# M36B register map
File version: 0.1
CPU: 
Registers are 32-bit, read-write, reset 0x0 unless marked. A register's access mark holds for its fields unless they carry their own. Offsets are from the block's base; [hi:lo] are bit positions; {n}, {i} and the like mark numbered series.

## PI — General Purpose Input_Output Port (PI)
Base 0x400C0800
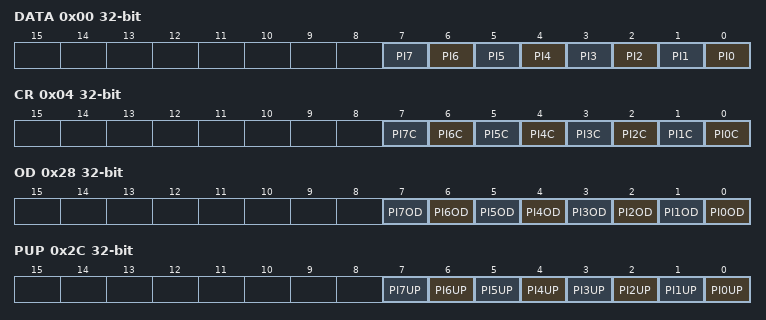
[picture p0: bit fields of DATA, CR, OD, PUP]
0x00 DATA — PI Data Register
  [n] PI{n} (n=0..7)
0x04 CR — PI Control Register
  [n] PI{n}C (n=0..7)
0x28 OD — PI Open Drain Control Register
  [n] PI{n}OD (n=0..7)
0x2C PUP — PI Pull-Up Control Register
  [n] PI{n}UP (n=0..7)
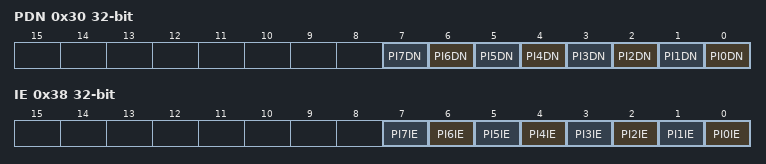
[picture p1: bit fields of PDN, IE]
0x30 PDN — PI Pull-Down Control Register
  [n] PI{n}DN (n=0..7)
0x38 IE — PI Input Enable Control Register
  [n] PI{n}IE (n=0..7)

## PJ — General Purpose Input_Output Port (PJ)
Base 0x400C0900
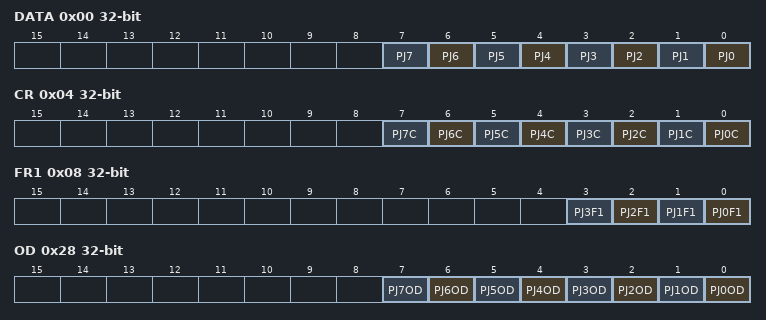
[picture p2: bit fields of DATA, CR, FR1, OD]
0x00 DATA — PJ Data Register
  [n] PJ{n} (n=0..7)
0x04 CR — PJ Control Register
  [n] PJ{n}C (n=0..7)
0x08 FR1 — PJ Function Register 1
  [n] PJ{n}F1 (n=0..3)
0x0C FR2 — PJ Function Register 2
  [3] PJ3F2
0x28 OD — PJ Open Drain Control Register
  [n] PJ{n}OD (n=0..7)
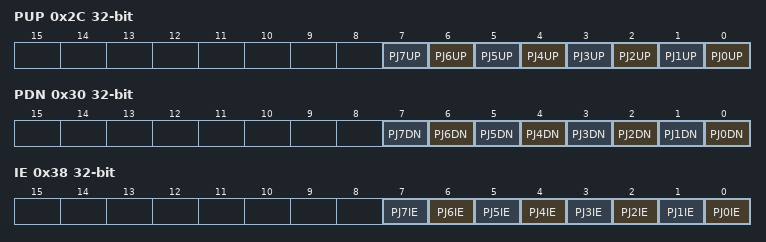
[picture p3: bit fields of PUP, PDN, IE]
0x2C PUP — PJ Pull-Up Control Register
  [n] PJ{n}UP (n=0..7)
0x30 PDN — PJ Pull-Down Control Register
  [n] PJ{n}DN (n=0..7)
0x38 IE — PJ Input Enable Control Register
  [n] PJ{n}IE (n=0..7)

## PK — General Purpose Input_Output Port (PK)
Base 0x400C0A00
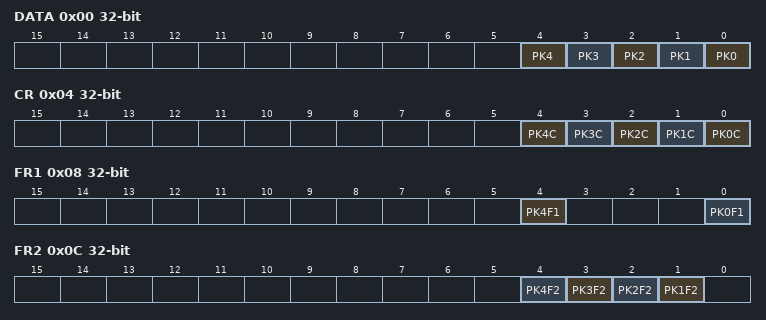
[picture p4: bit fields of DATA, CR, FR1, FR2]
0x00 DATA — PK Data Register
  [n] PK{n} (n=0..4)
0x04 CR — PK Control Register
  [n] PK{n}C (n=0..4)
0x08 FR1 — PK Function Register 1
  [4] PK4F1, [0] PK0F1
0x0C FR2 — PK Function Register 2
  [n] PK{n}F2 (n=1..4)
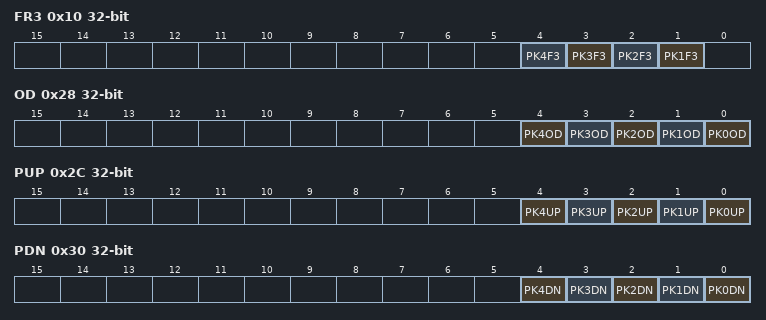
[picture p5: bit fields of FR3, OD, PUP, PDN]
0x10 FR3 — PK Function Register 3
  [n] PK{n}F3 (n=1..4)
0x14 FR4 — PK Function Register 4
  [1] PK1F4
0x28 OD — PK Open Drain Control Register
  [n] PK{n}OD (n=0..4)
0x2C PUP — PK Pull-Up Control Register
  [n] PK{n}UP (n=0..4)
0x30 PDN — PK Pull-Down Control Register
  [n] PK{n}DN (n=0..4)
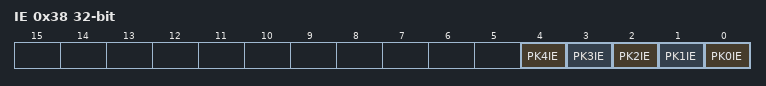
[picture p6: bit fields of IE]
0x38 IE — PK Input Enable Control Register
  [n] PK{n}IE (n=0..4)

## PL — General Purpose Input_Output Port (PL)
Base 0x400C0B00
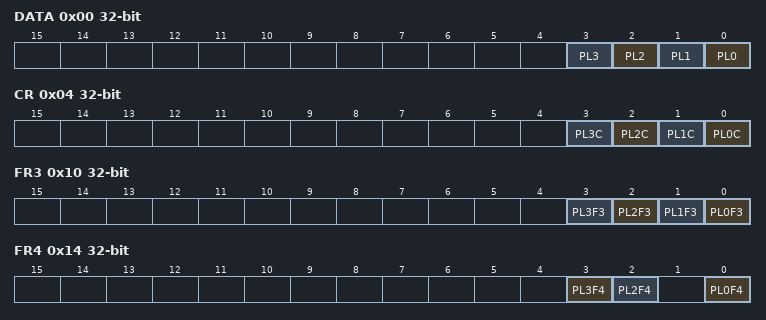
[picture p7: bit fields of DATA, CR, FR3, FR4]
0x00 DATA — PL Data Register
  [n] PL{n} (n=0..3)
0x04 CR — PL Control Register
  [n] PL{n}C (n=0..3)
0x0C FR2 — PL Function Register 2
  [0] PL0F2
0x10 FR3 — PL Function Register 3
  [n] PL{n}F3 (n=0..3)
0x14 FR4 — PL Function Register 4
  [3] PL3F4, [2] PL2F4, [0] PL0F4
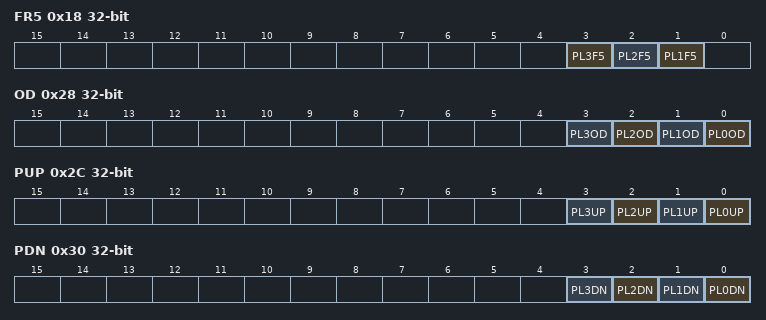
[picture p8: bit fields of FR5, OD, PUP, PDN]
0x18 FR5 — PL Function Register 5
  [3] PL3F5, [2] PL2F5, [1] PL1F5
0x1C FR6 — PL Function Register 6
  [3] PL3F6
0x28 OD — PL Open Drain Control Register
  [n] PL{n}OD (n=0..3)
0x2C PUP — PL Pull-Up Control Register
  [n] PL{n}UP (n=0..3)
0x30 PDN — PL Pull-Down Control Register
  [n] PL{n}DN (n=0..3)
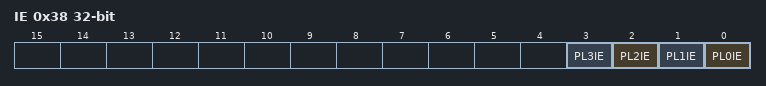
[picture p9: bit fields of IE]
0x38 IE — PL Input Enable Control Register
  [n] PL{n}IE (n=0..3)

## TB0 — 16-bit Timer_Event Counter (TB)
Base 0x400C4000
Same registers: TB1 0x400C4100, TB2 0x400C4200, TB3 0x400C4300, TB4 0x400C4400, TB5 0x400C4500, TB6 0x400C4600, TB7 0x400C4700
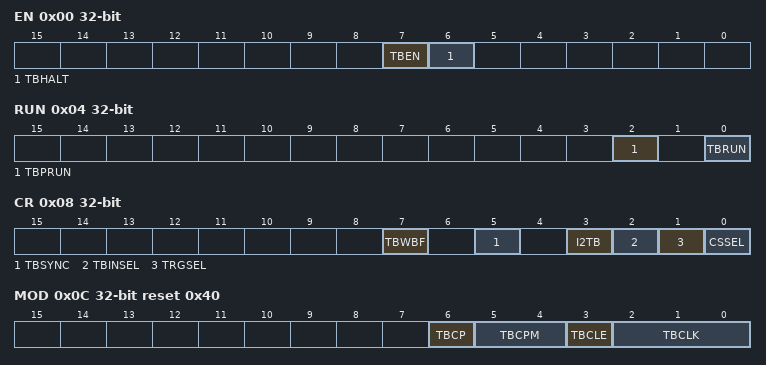
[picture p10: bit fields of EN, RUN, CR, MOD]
0x00 EN — TB Enable Register
  [7] TBEN, [6] TBHALT
0x04 RUN — TB RUN Register
  [2] TBPRUN, [0] TBRUN
0x08 CR — TB Control Register
  [7] TBWBF, [5] TBSYNC, [3] I2TB, [2] TBINSEL, [1] TRGSEL, [0] CSSEL
0x0C MOD reset 0x40 — TB Mode Register
  [6] TBCP wo, [5:4] TBCPM, [3] TBCLE, [2:0] TBCLK
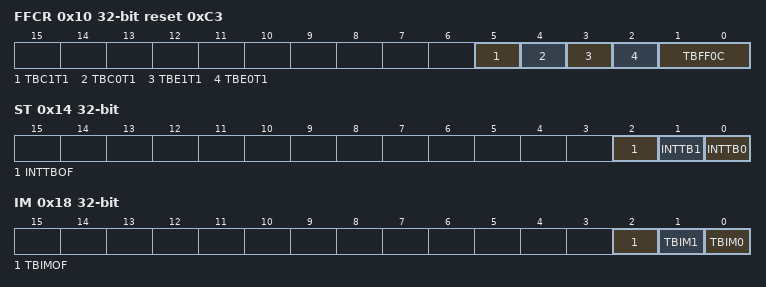
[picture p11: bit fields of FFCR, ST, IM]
0x10 FFCR reset 0xC3 — TB Flip-Flop Control Register
  [5] TBC1T1, [4] TBC0T1, [3] TBE1T1, [2] TBE0T1, [1:0] TBFF0C
0x14 ST ro — TB Status Register
  [2] INTTBOF, [1] INTTB1, [0] INTTB0
0x18 IM — TB Interrupt Mask Register
  [2] TBIMOF, [1] TBIM1, [0] TBIM0
0x1C UC ro — TB Read Capture Register
  [15:0] UC
0x20 RG0 — TB RG0 Timer Register
  [15:0] TBRG0
0x24 RG1 — TB RG1 Timer Register
  [15:0] TBRG1
0x28 CP0 ro (reset mask 0xFFFF0000) — TB CP0 Capture Register
  [15:0] TBCP0
0x2C CP1 ro (reset mask 0xFFFF0000) — TB CP1 Capture Register
  [15:0] TBCP1

## MT0 — 16-bit Multi-Purpose Timer (MPT-TMR_IGBT)
Base 0x400C7000
Same registers: MT1 0x400C7100, MT2 0x400C7200, MT3 0x400C7300
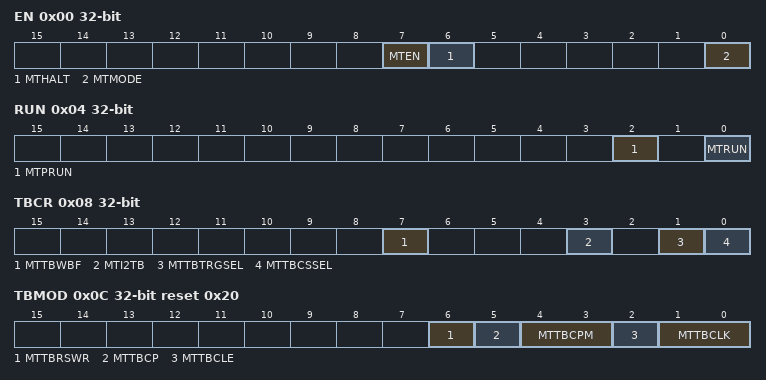
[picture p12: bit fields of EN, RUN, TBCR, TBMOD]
0x00 EN — MPT Enable Register
  [7] MTEN, [6] MTHALT, [0] MTMODE
0x04 RUN — MPT RUN Register
  [2] MTPRUN, [0] MTRUN
0x08 TBCR — MPT Control Register
  [7] MTTBWBF, [3] MTI2TB, [1] MTTBTRGSEL, [0] MTTBCSSEL
0x0C TBMOD reset 0x20 — MPT Mode Register
  [6] MTTBRSWR, [5] MTTBCP wo, [4:3] MTTBCPM, [2] MTTBCLE, [1:0] MTTBCLK
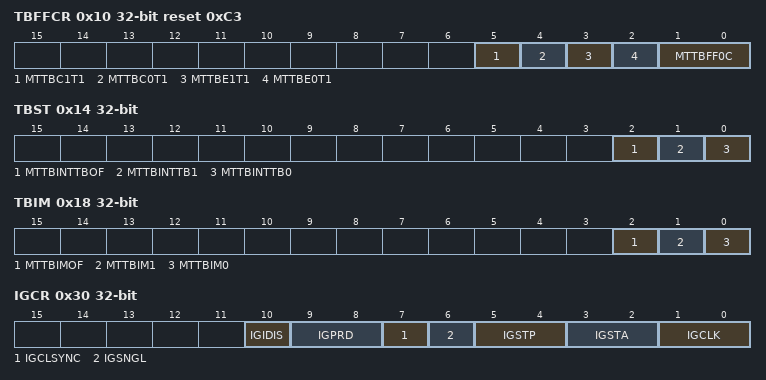
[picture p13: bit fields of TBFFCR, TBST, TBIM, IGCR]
0x10 TBFFCR reset 0xC3 — MPT Flip-Flop Control Register
  [5] MTTBC1T1, [4] MTTBC0T1, [3] MTTBE1T1, [2] MTTBE0T1, [1:0] MTTBFF0C
0x14 TBST ro — MPT Status Register
  [2] MTTBINTTBOF, [1] MTTBINTTB1, [0] MTTBINTTB0
0x18 TBIM — MPT Interrupt Mask Register
  [2] MTTBIMOF, [1] MTTBIM1, [0] MTTBIM0
0x1C TBUC ro — MPT Read Capture Register
  [15:0] MTUC
0x20 RG0 — MPT RG0 Timer Register
  [15:0] MTRG0
0x24 RG1 — MPT RG1 Timer Register
  [15:0] MTRG1
0x28 CP0 ro — MPT CP0 Capture Register
  [15:0] MTCP0
0x2C CP1 ro — MPT CP1 Capture Register
  [15:0] MTCP1
0x30 IGCR — IGBT Control Register
  [10] IGIDIS, [9:8] IGPRD, [7] IGCLSYNC, [6] IGSNGL, [5:4] IGSTP, [3:2] IGSTA, [1:0] IGCLK
0x34 IGRESTA wo — IGBT Timer Restart Register
  [0] IGRESTA
0x38 IGST ro — IGBT Timer Status Register
  [0] IGST
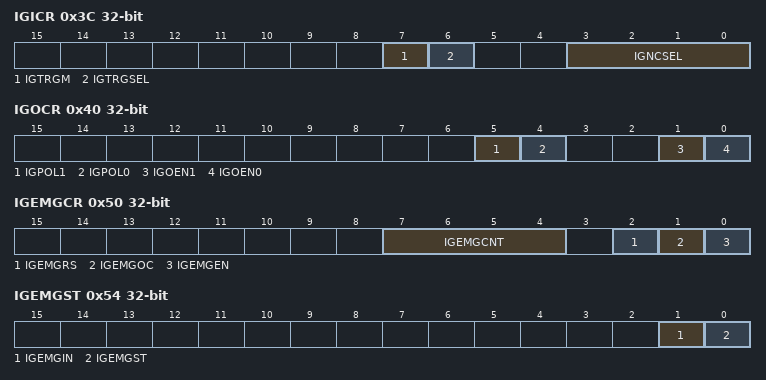
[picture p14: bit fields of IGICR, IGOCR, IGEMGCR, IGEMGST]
0x3C IGICR — IGBT Input Control Register
  [7] IGTRGM, [6] IGTRGSEL, [3:0] IGNCSEL
0x40 IGOCR — IGBT Output Control Register
  [5] IGPOL1, [4] IGPOL0, [1] IGOEN1, [0] IGOEN0
{0x3C+4i} IGRG{i} (i=2..4) — IGBT RG{i} Timer Register
  [15:0] IGRG{i}
0x50 IGEMGCR — IGBT EMG Control Register
  [7:4] IGEMGCNT, [2] IGEMGRS wo, [1] IGEMGOC, [0] IGEMGEN
0x54 IGEMGST ro — IGBT EMG Status Register
  [1] IGEMGIN, [0] IGEMGST
0x58 IGTRG — IGBT Trigger Register
  [15:0] IGTRG
